# GD32C11x register map
File version: 1.0
CPU: CM4 r2p1, little endian, no MPU, FPU, 4 interrupt priority bits
Registers are 32-bit, read-write, reset 0x0 unless marked. A register's access mark holds for its fields unless they carry their own. Offsets are from the block's base; [hi:lo] are bit positions; {n}, {i} and the like mark numbered series.

## EXMC — External memory controller
Base 0xA0000000
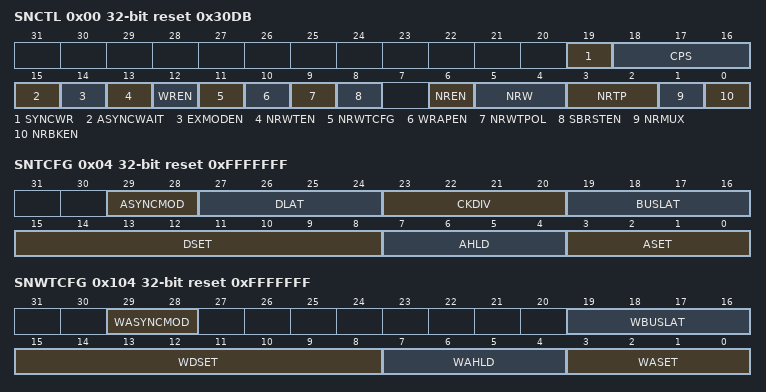
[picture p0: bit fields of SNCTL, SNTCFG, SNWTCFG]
0x00 SNCTL reset 0x30DB — SRAM/NOR Flash control registers
  [19] SYNCWR — synchronous write
  [18:16] CPS — CRAM page size
  [15] ASYNCWAIT — asynchronous wait
  [14] EXMODEN — extended mode enable
  [13] NRWTEN — NWAIT signal enable
  [12] WREN — write enable
  [11] NRWTCFG — NWAIT signal configuration
  [10] WRAPEN — wrapped burst mode enable
  [9] NRWTPOL — NWAIT signal polarity
  [8] SBRSTEN — synchronous burst enable
  [6] NREN — NOR Flash access enable
  [5:4] NRW — NOR region memory data bus width
  [3:2] NRTP — NOR region memory type
  [1] NRMUX — NOR region memory address/data multiplexing
  [0] NRBKEN — NOR region enable
0x04 SNTCFG reset 0xFFFFFFF — SRAM/NOR Flash timing configuration registers
  [29:28] ASYNCMOD — asynchronous access mode
  [27:24] DLAT — data latency for NOR Flash
  [23:20] CKDIV — synchronous clock divide ratio
  [19:16] BUSLAT — bus latency
  [15:8] DSET — data setup time
  [7:4] AHLD — address hold time
  [3:0] ASET — address setup time
0x104 SNWTCFG reset 0xFFFFFFF — SRAM/NOR write timing configuration registers
  [29:28] WASYNCMOD — asynchronous access mode
  [19:16] WBUSLAT — bus latency
  [15:8] WDSET — data setup time
  [7:4] WAHLD — address hold time
  [3:0] WASET — address setup time

## EXTI — External interrupt/event controller
Base 0x40010400
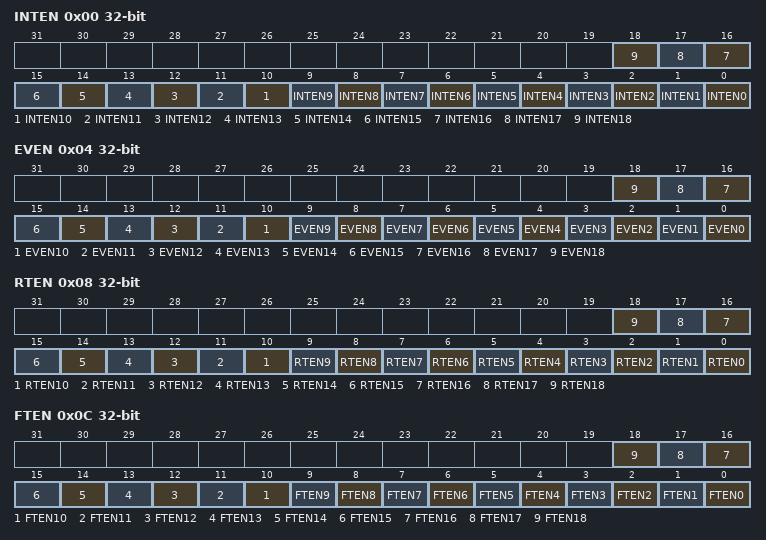
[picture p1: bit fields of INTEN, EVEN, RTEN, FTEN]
0x00 INTEN — Interrupt enable register
  [n] INTEN{n} (n=0..18) — Enable Interrupt on line {n}
0x04 EVEN — Event enable register
  [n] EVEN{n} (n=0..18) — Enable Event on line {n}
0x08 RTEN — Rising edge trigger enable register
  [n] RTEN{n} (n=0..18) — Rising edge trigger enable of line {n}
0x0C FTEN — Falling Egde Trigger Enable register
  [n] FTEN{n} (n=0..18) — Falling edge trigger enable of line {n}
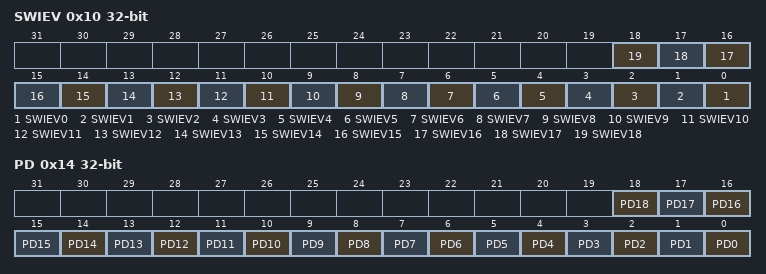
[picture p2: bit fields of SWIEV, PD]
0x10 SWIEV — Software interrupt event register
  [n] SWIEV{n} (n=0..18) — Interrupt/Event software trigger on line {n}
0x14 PD — Pending register (EXTI_PD)
  [n] PD{n} (n=0..18) — Interrupt pending status of line {n}

## FMC
Base 0x40022000
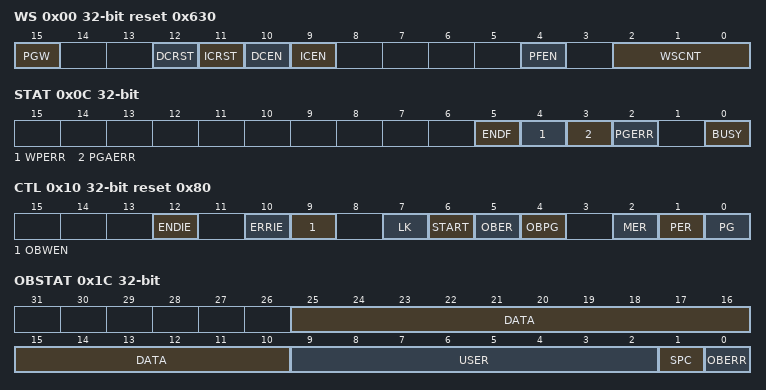
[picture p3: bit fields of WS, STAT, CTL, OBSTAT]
0x00 WS reset 0x630 — wait state register
  [15] PGW — Program width to flash memory
  [12] DCRST — DBUS cache reset
  [11] ICRST — IBUS cache reset
  [10] DCEN — DBUS cache enable
  [9] ICEN — IBUS cache enable
  [4] PFEN — Pre-fetch enable
  [2:0] WSCNT — wait state counter register
0x04 KEY wo — Unlock key register
  [31:0] KEY — FMC_CTL unlock register
0x08 OBKEY wo — Option byte unlock key register
  [31:0] OBKEY — FMC_ CTL option bytes operation unlock register
0x0C STAT access per field — Status register
  [5] ENDF rw — End of operation flag bit
  [4] WPERR rw — Erase/Program protection error flag bit
  [3] PGAERR rw — Program alignment error flag bit
  [2] PGERR rw — Program error flag bit
  [0] BUSY ro — The flash is busy bit
0x10 CTL reset 0x80 — Control register
  [12] ENDIE — End of operation interrupt enable bit
  [10] ERRIE — Error interrupt enable bit
  [9] OBWEN — Option byte erase/program enable bit
  [7] LK — FMC_CTL lock bit
  [6] START — Send erase command to FMC bit
  [5] OBER — Option bytes erase command bit
  [4] OBPG — Option bytes program command bit
  [2] MER — Main flash mass erase for bank0 command bit
  [1] PER — Main flash page erase for bank0 command bit
  [0] PG — Main flash program for bank0 command bit
0x14 ADDR wo — Address register
  [31:0] ADDR — Flash erase/program command address bits
0x1C OBSTAT ro — Option byte control register
  [25:10] DATA — Store DATA[15:0] of option bytes block after system reset
  [9:2] USER — Store USER of option bytes block after system reset
  [1] SPC — Option bytes security protection code
  [0] OBERR — Option bytes read error bit
0x20 WP ro — Erase/Program Protection register
  [31:0] WP — Store WP[31:0] of option bytes block after system reset
0x100 PID ro — Product ID register
  [31:0] PID — Product reserved ID code register
